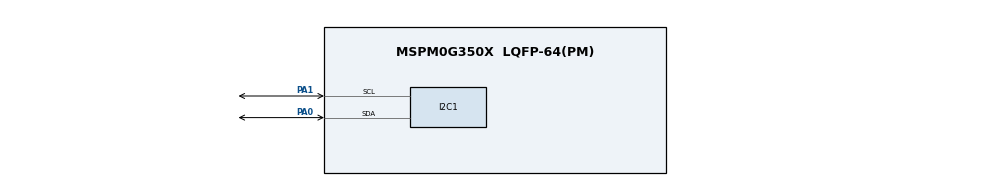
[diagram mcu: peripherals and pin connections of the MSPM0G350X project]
/**
 * @cliArgs --device "MSPM0G350X" --part "Default" --package "LQFP-64(PM)" --product "mspm0_sdk@2.10.00.04"
 * @versions {"tool":"1.26.2+4477"}
 */

const I2C    = scripting.addModule("/ti/driverlib/I2C", {}, false);
const I2C1   = I2C.addInstance();
const SYSCTL = scripting.addModule("/ti/driverlib/SYSCTL");

I2C1.$name                       = "I2C";
I2C1.basicEnableController       = true;
I2C1.basicControllerBusSpeed     = 400000;
I2C1.advAnalogGlitchFilter       = "DISABLED";
I2C1.peripheral.sclPin.$assign   = "PA1";
I2C1.peripheral.sdaPin.$assign   = "PA0";

const Board = scripting.addModule("/ti/driverlib/Board", {}, false);

SYSCTL.forceDefaultClkConfig = true;
Board.peripheral.$suggestSolution          = "DEBUGSS";
Board.peripheral.swclkPin.$suggestSolution = "PA20";
Board.peripheral.swdioPin.$suggestSolution = "PA19";
SYSCTL.peripheral.$suggestSolution         = "SYSCTL";
